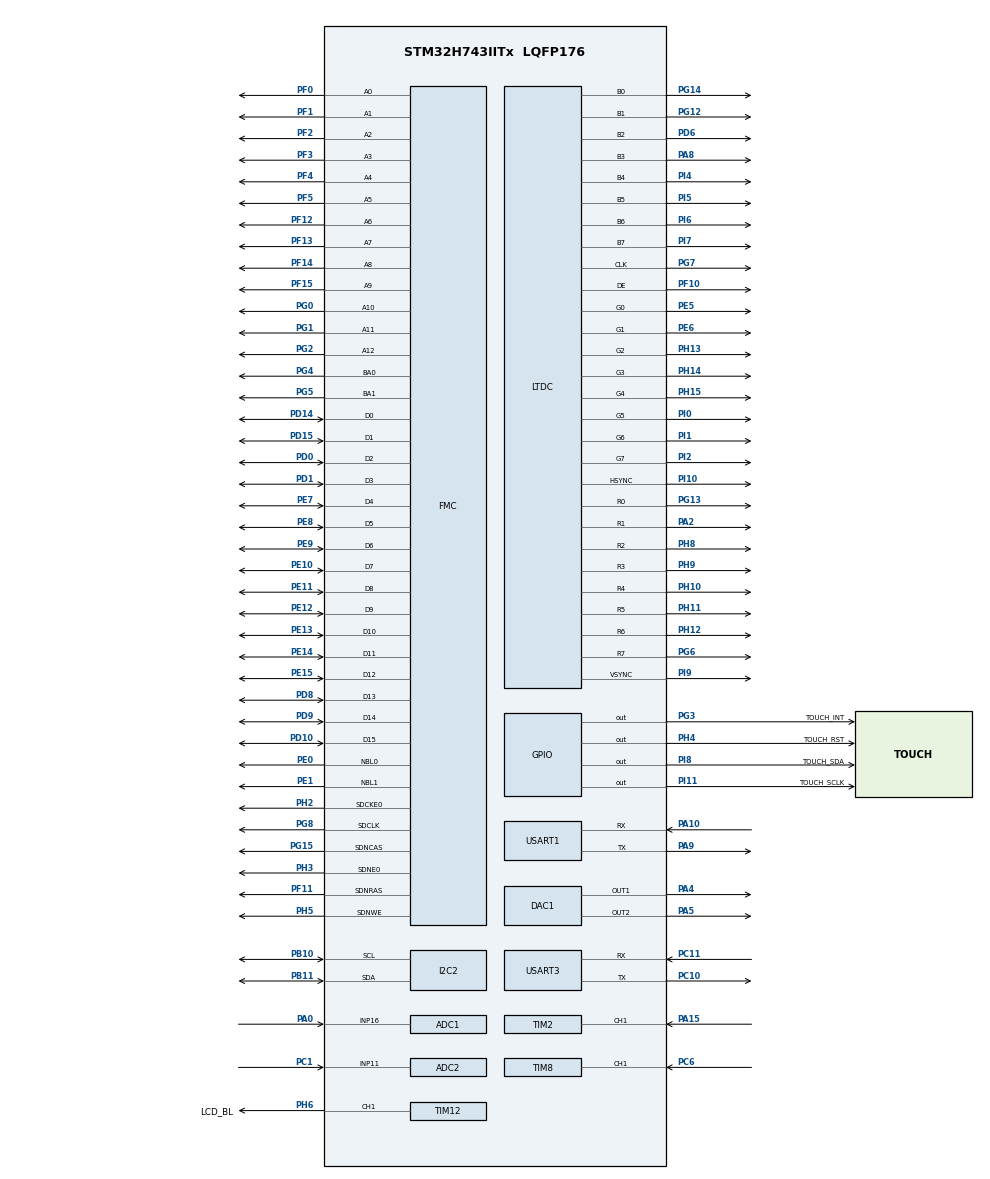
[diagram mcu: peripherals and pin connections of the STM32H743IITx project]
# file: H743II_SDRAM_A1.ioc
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ADC1.Channel-0\#ChannelRegularConversion=ADC_CHANNEL_16
ADC1.ConversionDataManagement=ADC_CONVERSIONDATA_DMA_CIRCULAR
ADC1.ExternalTrigConv=ADC_EXTERNALTRIG_T2_TRGO
ADC1.NbrOfConversionFlag=1
ADC1.OffsetNumber-0\#ChannelRegularConversion=ADC_OFFSET_NONE
ADC1.OffsetSignedSaturation-0\#ChannelRegularConversion=DISABLE
ADC1.Overrun=ADC_OVR_DATA_OVERWRITTEN
ADC1.Rank-0\#ChannelRegularConversion=1
ADC1.Resolution=ADC_RESOLUTION_8B
ADC1.SamplingTime-0\#ChannelRegularConversion=ADC_SAMPLETIME_1CYCLE_5
ADC1.master=1
ADC2.Channel-0\#ChannelRegularConversion=ADC_CHANNEL_11
ADC2.ConversionDataManagement=ADC_CONVERSIONDATA_DMA_CIRCULAR
ADC2.ExternalTrigConv=ADC_EXTERNALTRIG_T8_TRGO
ADC2.NbrOfConversionFlag=1
ADC2.OffsetNumber-0\#ChannelRegularConversion=ADC_OFFSET_NONE
ADC2.OffsetSignedSaturation-0\#ChannelRegularConversion=DISABLE
ADC2.Overrun=ADC_OVR_DATA_OVERWRITTEN
ADC2.Rank-0\#ChannelRegularConversion=1
ADC2.Resolution=ADC_RESOLUTION_8B
ADC2.SamplingTime-0\#ChannelRegularConversion=ADC_SAMPLETIME_1CYCLE_5
CORTEX_M7.AccessPermission-Cortex_Memory_Protection_Unit_Region0_Settings=MPU_REGION_FULL_ACCESS
CORTEX_M7.AccessPermission-Cortex_Memory_Protection_Unit_Region1_Settings=MPU_REGION_FULL_ACCESS
CORTEX_M7.AccessPermission-Cortex_Memory_Protection_Unit_Region2_Settings=MPU_REGION_FULL_ACCESS
CORTEX_M7.BaseAddress-Cortex_Memory_Protection_Unit_Region0_Settings=0x24000000
CORTEX_M7.BaseAddress-Cortex_Memory_Protection_Unit_Region1_Settings=0x30000000
CORTEX_M7.BaseAddress-Cortex_Memory_Protection_Unit_Region2_Settings=0xC0000000
CORTEX_M7.CPU_DCache=Enabled
CORTEX_M7.CPU_ICache=Enabled
CORTEX_M7.DisableExec-Cortex_Memory_Protection_Unit_Region0_Settings=MPU_INSTRUCTION_ACCESS_DISABLE
CORTEX_M7.DisableExec-Cortex_Memory_Protection_Unit_Region1_Settings=MPU_INSTRUCTION_ACCESS_DISABLE
CORTEX_M7.Enable-Cortex_Memory_Protection_Unit_Region0_Settings=MPU_REGION_ENABLE
CORTEX_M7.Enable-Cortex_Memory_Protection_Unit_Region1_Settings=MPU_REGION_ENABLE
CORTEX_M7.Enable-Cortex_Memory_Protection_Unit_Region2_Settings=MPU_REGION_ENABLE
CORTEX_M7.IsBufferable-Cortex_Memory_Protection_Unit_Region0_Settings=MPU_ACCESS_BUFFERABLE
CORTEX_M7.IsCacheable-Cortex_Memory_Protection_Unit_Region0_Settings=MPU_ACCESS_CACHEABLE
CORTEX_M7.MPU_Control=MPU_PRIVILEGED_DEFAULT
CORTEX_M7.Size-Cortex_Memory_Protection_Unit_Region0_Settings=MPU_REGION_SIZE_64KB
CORTEX_M7.Size-Cortex_Memory_Protection_Unit_Region1_Settings=MPU_REGION_SIZE_16KB
CORTEX_M7.Size-Cortex_Memory_Protection_Unit_Region2_Settings=MPU_REGION_SIZE_32MB
CORTEX_M7.TypeExtField-Cortex_Memory_Protection_Unit_Region1_Settings=MPU_TEX_LEVEL1
DAC1.DAC_Channel-DAC_OUT1=DAC_CHANNEL_1
DAC1.DAC_Channel-DAC_OUT2=DAC_CHANNEL_2
DAC1.DAC_Trigger-DAC_OUT1=DAC_TRIGGER_T2_TRGO
DAC1.DAC_Trigger-DAC_OUT2=DAC_TRIGGER_T8_TRGO
DMA2D.ColorMode=DMA2D_OUTPUT_ARGB8888
Dma.ADC1.0.Direction=DMA_PERIPH_TO_MEMORY
Dma.ADC1.0.EventEnable=DISABLE
Dma.ADC1.0.FIFOMode=DMA_FIFOMODE_DISABLE
Dma.ADC1.0.Instance=DMA1_Stream0
Dma.ADC1.0.MemDataAlignment=DMA_MDATAALIGN_BYTE
Dma.ADC1.0.MemInc=DMA_MINC_ENABLE
Dma.ADC1.0.Mode=DMA_CIRCULAR
Dma.ADC1.0.PeriphDataAlignment=DMA_PDATAALIGN_BYTE
Dma.ADC1.0.PeriphInc=DMA_PINC_DISABLE
Dma.ADC1.0.Polarity=HAL_DMAMUX_REQ_GEN_RISING
Dma.ADC1.0.Priority=DMA_PRIORITY_LOW
Dma.ADC1.0.RequestNumber=1
Dma.ADC1.0.SignalID=NONE
Dma.ADC1.0.SyncEnable=DISABLE
Dma.ADC1.0.SyncPolarity=HAL_DMAMUX_SYNC_NO_EVENT
Dma.ADC1.0.SyncRequestNumber=1
Dma.ADC1.0.SyncSignalID=NONE
Dma.ADC2.1.Direction=DMA_PERIPH_TO_MEMORY
Dma.ADC2.1.EventEnable=DISABLE
Dma.ADC2.1.FIFOMode=DMA_FIFOMODE_DISABLE
Dma.ADC2.1.Instance=DMA1_Stream1
Dma.ADC2.1.MemDataAlignment=DMA_MDATAALIGN_BYTE
Dma.ADC2.1.MemInc=DMA_MINC_ENABLE
Dma.ADC2.1.Mode=DMA_CIRCULAR
Dma.ADC2.1.PeriphDataAlignment=DMA_PDATAALIGN_BYTE
Dma.ADC2.1.PeriphInc=DMA_PINC_DISABLE
Dma.ADC2.1.Polarity=HAL_DMAMUX_REQ_GEN_RISING
Dma.ADC2.1.Priority=DMA_PRIORITY_LOW
Dma.ADC2.1.RequestNumber=1
Dma.ADC2.1.SignalID=NONE
Dma.ADC2.1.SyncEnable=DISABLE
Dma.ADC2.1.SyncPolarity=HAL_DMAMUX_SYNC_NO_EVENT
Dma.ADC2.1.SyncRequestNumber=1
Dma.ADC2.1.SyncSignalID=NONE
Dma.DAC1_CH1.2.Direction=DMA_MEMORY_TO_PERIPH
Dma.DAC1_CH1.2.EventEnable=DISABLE
Dma.DAC1_CH1.2.FIFOMode=DMA_FIFOMODE_DISABLE
Dma.DAC1_CH1.2.Instance=DMA1_Stream2
Dma.DAC1_CH1.2.MemDataAlignment=DMA_MDATAALIGN_HALFWORD
Dma.DAC1_CH1.2.MemInc=DMA_MINC_ENABLE
Dma.DAC1_CH1.2.Mode=DMA_CIRCULAR
Dma.DAC1_CH1.2.PeriphDataAlignment=DMA_PDATAALIGN_HALFWORD
Dma.DAC1_CH1.2.PeriphInc=DMA_PINC_DISABLE
Dma.DAC1_CH1.2.Polarity=HAL_DMAMUX_REQ_GEN_RISING
Dma.DAC1_CH1.2.Priority=DMA_PRIORITY_LOW
Dma.DAC1_CH1.2.RequestNumber=1
Dma.DAC1_CH1.2.SignalID=NONE
Dma.DAC1_CH1.2.SyncEnable=DISABLE
Dma.DAC1_CH1.2.SyncPolarity=HAL_DMAMUX_SYNC_NO_EVENT
Dma.DAC1_CH1.2.SyncRequestNumber=1
Dma.DAC1_CH1.2.SyncSignalID=NONE
Dma.DAC1_CH2.3.Direction=DMA_MEMORY_TO_PERIPH
Dma.DAC1_CH2.3.EventEnable=DISABLE
Dma.DAC1_CH2.3.FIFOMode=DMA_FIFOMODE_DISABLE
Dma.DAC1_CH2.3.Instance=DMA1_Stream3
Dma.DAC1_CH2.3.MemDataAlignment=DMA_MDATAALIGN_HALFWORD
Dma.DAC1_CH2.3.MemInc=DMA_MINC_ENABLE
Dma.DAC1_CH2.3.Mode=DMA_CIRCULAR
Dma.DAC1_CH2.3.PeriphDataAlignment=DMA_PDATAALIGN_HALFWORD
Dma.DAC1_CH2.3.PeriphInc=DMA_PINC_DISABLE
Dma.DAC1_CH2.3.Polarity=HAL_DMAMUX_REQ_GEN_RISING
Dma.DAC1_CH2.3.Priority=DMA_PRIORITY_LOW
Dma.DAC1_CH2.3.RequestNumber=1
Dma.DAC1_CH2.3.SignalID=NONE
Dma.DAC1_CH2.3.SyncEnable=DISABLE
Dma.DAC1_CH2.3.SyncPolarity=HAL_DMAMUX_SYNC_NO_EVENT
Dma.DAC1_CH2.3.SyncRequestNumber=1
Dma.DAC1_CH2.3.SyncSignalID=NONE
Dma.Request0=ADC1
Dma.Request1=ADC2
Dma.Request2=DAC1_CH1
Dma.Request3=DAC1_CH2
FMC.CASLatency1=FMC_SDRAM_CAS_LATENCY_3
FMC.ColumnBitsNumber1=FMC_SDRAM_COLUMN_BITS_NUM_9
FMC.ExitSelfRefreshDelay1=9
FMC.LoadToActiveDelay1=2
FMC.RCDDelay1=3
FMC.RPDelay1=3
FMC.RPDelay2=3
FMC.ReadBurst1=FMC_SDRAM_RBURST_ENABLE
FMC.ReadBurst2=FMC_SDRAM_RBURST_ENABLE
FMC.ReadPipeDelay1=FMC_SDRAM_RPIPE_DELAY_1
FMC.ReadPipeDelay2=FMC_SDRAM_RPIPE_DELAY_1
FMC.RowCycleDelay1=8
FMC.RowCycleDelay2=8
FMC.SDClockPeriod1=FMC_SDRAM_CLOCK_PERIOD_2
FMC.SDClockPeriod2=FMC_SDRAM_CLOCK_PERIOD_2
FMC.SelfRefreshTime1=6
FMC.WriteRecoveryTime1=2
I2C2.Timing=0x307075B1
LTDC.ActiveW=800
LTDC.Alpha_L0=255
LTDC.BlendingFactor1_L0=LTDC_BLENDING_FACTOR1_PAxCA
LTDC.BlendingFactor2_L0=LTDC_BLENDING_FACTOR2_PAxCA
LTDC.FBStartAdress_L0=0xC0000000
LTDC.HBP=80
LTDC.HFP=200
LTDC.HSync=1
LTDC.ImageHeight_L0=480
LTDC.ImageWidth_L0=800
LTDC.Layers=0
LTDC.PixelFormat_L0=LTDC_PIXEL_FORMAT_ARGB8888
LTDC.VBP=40
LTDC.VFP=22
LTDC.VSync=1
LTDC.WindowX1_L0=800
LTDC.WindowY1_L0=480
Mcu.Family=STM32H7
Mcu.Name=STM32H743IITx
Mcu.Package=LQFP176
NVIC.DMA1_Stream0_IRQn=true\:0\:0\:false\:false\:true\:false\:true\:true
NVIC.DMA1_Stream1_IRQn=true\:0\:0\:false\:false\:true\:false\:true\:true
NVIC.DMA1_Stream2_IRQn=true\:0\:0\:false\:false\:true\:false\:true\:true
NVIC.DMA1_Stream3_IRQn=true\:0\:0\:false\:false\:true\:false\:true\:true
NVIC.PriorityGroup=NVIC_PRIORITYGROUP_4
PA0.Mode=IN16-Single-Ended
PA0.Signal=ADC1_INP16
PA10.Mode=Asynchronous
PA10.Signal=USART1_RX
PA13\ (JTMS/SWDIO).Mode=Serial_Wire
PA13\ (JTMS/SWDIO).Signal=DEBUG_JTMS-SWDIO
PA14\ (JTCK/SWCLK).Mode=Serial_Wire
PA14\ (JTCK/SWCLK).Signal=DEBUG_JTCK-SWCLK
PA15\ (JTDI).Signal=S_TIM2_CH1_ETR
PA2.GPIO_Speed=GPIO_SPEED_FREQ_HIGH
PA2.Mode=RGB888
PA2.Signal=LTDC_R1
PA4.Signal=COMP_DAC11_group
PA5.Signal=COMP_DAC12_group
PA8.GPIO_Speed=GPIO_SPEED_FREQ_HIGH
PA8.Mode=RGB888
PA8.Signal=LTDC_B3
PA9.Mode=Asynchronous
PA9.Signal=USART1_TX
PB10.Mode=I2C
PB10.Signal=I2C2_SCL
PB11.Mode=I2C
PB11.Signal=I2C2_SDA
PC1.Signal=ADCx_INP11
PC10.Mode=Asynchronous
PC10.Signal=USART3_TX
PC11.Mode=Asynchronous
PC11.Signal=USART3_RX
PC14-OSC32_IN\ (OSC32_IN).Mode=LSE-External-Oscillator
PC14-OSC32_IN\ (OSC32_IN).Signal=RCC_OSC32_IN
PC15-OSC32_OUT\ (OSC32_OUT).Mode=LSE-External-Oscillator
PC15-OSC32_OUT\ (OSC32_OUT).Signal=RCC_OSC32_OUT
PC6.Signal=S_TIM8_CH1
PD0.Signal=FMC_D2_DA2
PD1.Signal=FMC_D3_DA3
PD10.Signal=FMC_D15_DA15
PD14.Signal=FMC_D0_DA0
PD15.Signal=FMC_D1_DA1
PD6.GPIO_Speed=GPIO_SPEED_FREQ_HIGH
PD6.Mode=RGB888
PD6.Signal=LTDC_B2
PD8.Signal=FMC_D13_DA13
PD9.Signal=FMC_D14_DA14
PE0.Signal=FMC_NBL0
PE1.Signal=FMC_NBL1
PE10.Signal=FMC_D7_DA7
PE11.Signal=FMC_D8_DA8
PE12.Signal=FMC_D9_DA9
PE13.Signal=FMC_D10_DA10
PE14.Signal=FMC_D11_DA11
PE15.Signal=FMC_D12_DA12
PE5.GPIO_Speed=GPIO_SPEED_FREQ_HIGH
PE5.Mode=RGB888
PE5.Signal=LTDC_G0
PE6.GPIO_Speed=GPIO_SPEED_FREQ_HIGH
PE6.Mode=RGB888
PE6.Signal=LTDC_G1
PE7.Signal=FMC_D4_DA4
PE8.Signal=FMC_D5_DA5
PE9.Signal=FMC_D6_DA6
PF0.Signal=FMC_A0
PF1.Signal=FMC_A1
PF10.GPIO_Speed=GPIO_SPEED_FREQ_HIGH
PF10.Mode=RGB888
PF10.Signal=LTDC_DE
PF11.Signal=FMC_SDNRAS
PF12.Signal=FMC_A6
PF13.Signal=FMC_A7
PF14.Signal=FMC_A8
PF15.Signal=FMC_A9
PF2.Signal=FMC_A2
PF3.Signal=FMC_A3
PF4.Signal=FMC_A4
PF5.Signal=FMC_A5
PG0.Signal=FMC_A10
PG1.Signal=FMC_A11
PG12.GPIO_Speed=GPIO_SPEED_FREQ_HIGH
PG12.Mode=RGB888
PG12.Signal=LTDC_B1
PG13.GPIO_Speed=GPIO_SPEED_FREQ_HIGH
PG13.Mode=RGB888
PG13.Signal=LTDC_R0
PG14.GPIO_Speed=GPIO_SPEED_FREQ_HIGH
PG14.Mode=RGB888
PG14.Signal=LTDC_B0
PG15.Signal=FMC_SDNCAS
PG2.Signal=FMC_A12
PG3.GPIO_Label=TOUCH_INT
PG3.GPIO_ModeDefaultOutputPP=GPIO_MODE_OUTPUT_PP
PG3.GPIO_PuPd=GPIO_NOPULL
PG3.GPIO_Speed=GPIO_SPEED_FREQ_LOW
PG3.PinState=GPIO_PIN_RESET
PG3.Signal=GPIO_Output
PG4.Signal=FMC_A14_BA0
PG5.Signal=FMC_A15_BA1
PG6.GPIO_Speed=GPIO_SPEED_FREQ_HIGH
PG6.Mode=RGB888
PG6.Signal=LTDC_R7
PG7.GPIO_Speed=GPIO_SPEED_FREQ_HIGH
PG7.Mode=RGB888
PG7.Signal=LTDC_CLK
PG8.Signal=FMC_SDCLK
PH0-OSC_IN\ (PH0).Mode=HSE-External-Oscillator
PH0-OSC_IN\ (PH0).Signal=RCC_OSC_IN
PH1-OSC_OUT\ (PH1).Mode=HSE-External-Oscillator
PH1-OSC_OUT\ (PH1).Signal=RCC_OSC_OUT
PH10.GPIO_Speed=GPIO_SPEED_FREQ_HIGH
PH10.Mode=RGB888
PH10.Signal=LTDC_R4
PH11.GPIO_Speed=GPIO_SPEED_FREQ_HIGH
PH11.Mode=RGB888
PH11.Signal=LTDC_R5
PH12.GPIO_Speed=GPIO_SPEED_FREQ_HIGH
PH12.Mode=RGB888
PH12.Signal=LTDC_R6
PH13.GPIO_Speed=GPIO_SPEED_FREQ_HIGH
PH13.Mode=RGB888
PH13.Signal=LTDC_G2
PH14.GPIO_Speed=GPIO_SPEED_FREQ_HIGH
PH14.Mode=RGB888
PH14.Signal=LTDC_G3
PH15.GPIO_Speed=GPIO_SPEED_FREQ_HIGH
PH15.Mode=RGB888
PH15.Signal=LTDC_G4
PH2.Mode=SdramChipSelect1_1
PH2.Signal=FMC_SDCKE0
PH3.Mode=SdramChipSelect1_1
PH3.Signal=FMC_SDNE0
PH4.GPIO_Label=TOUCH_RST
PH4.GPIO_Speed=GPIO_SPEED_FREQ_LOW
PH4.PinState=GPIO_PIN_SET
PH4.Signal=GPIO_Output
PH5.Signal=FMC_SDNWE
PH6.GPIO_Label=LCD_BL
PH6.Signal=S_TIM12_CH1
PH8.GPIO_Speed=GPIO_SPEED_FREQ_HIGH
PH8.Mode=RGB888
PH8.Signal=LTDC_R2
PH9.GPIO_Speed=GPIO_SPEED_FREQ_HIGH
PH9.Mode=RGB888
PH9.Signal=LTDC_R3
PI0.GPIO_Speed=GPIO_SPEED_FREQ_HIGH
PI0.Mode=RGB888
PI0.Signal=LTDC_G5
PI1.GPIO_Speed=GPIO_SPEED_FREQ_HIGH
PI1.Mode=RGB888
PI1.Signal=LTDC_G6
PI10.GPIO_Speed=GPIO_SPEED_FREQ_HIGH
PI10.Mode=RGB888
PI10.Signal=LTDC_HSYNC
PI11.GPIO_Label=TOUCH_SCLK
PI11.GPIO_ModeDefaultOutputPP=GPIO_MODE_OUTPUT_OD
PI11.GPIO_PuPd=GPIO_NOPULL
PI11.GPIO_Speed=GPIO_SPEED_FREQ_LOW
PI11.PinState=GPIO_PIN_SET
PI11.Signal=GPIO_Output
PI2.GPIO_Speed=GPIO_SPEED_FREQ_HIGH
PI2.Mode=RGB888
PI2.Signal=LTDC_G7
PI4.GPIO_Speed=GPIO_SPEED_FREQ_HIGH
PI4.Mode=RGB888
PI4.Signal=LTDC_B4
PI5.GPIO_Speed=GPIO_SPEED_FREQ_HIGH
PI5.Mode=RGB888
PI5.Signal=LTDC_B5
PI6.GPIO_Speed=GPIO_SPEED_FREQ_HIGH
PI6.Mode=RGB888
PI6.Signal=LTDC_B6
PI7.GPIO_Speed=GPIO_SPEED_FREQ_HIGH
PI7.Mode=RGB888
PI7.Signal=LTDC_B7
PI8.GPIO_Label=TOUCH_SDA
PI8.Signal=GPIO_Output
PI9.GPIO_Speed=GPIO_SPEED_FREQ_HIGH
PI9.Mode=RGB888
PI9.Signal=LTDC_VSYNC
ProjectManager.HeapSize=0x1600
ProjectManager.StackSize=0x2000
ProjectManager.TargetToolchain=MDK-ARM V5.32
RCC.ADCFreq_Value=75000000
RCC.APB1Freq_Value=120000000
RCC.APB2Freq_Value=120000000
RCC.APB3Freq_Value=120000000
RCC.APB4Freq_Value=120000000
RCC.CortexFreq_Value=480000000
RCC.D1PPRE=RCC_APB3_DIV2
RCC.D2PPRE1=RCC_APB1_DIV2
RCC.D2PPRE2=RCC_APB2_DIV2
RCC.D3PPRE=RCC_APB4_DIV2
RCC.DIVM1=5
RCC.DIVM2=2
RCC.DIVM3=25
RCC.DIVN1=192
RCC.DIVN2=12
RCC.DIVN3=264
RCC.DIVQ3=8
RCC.DIVR3=8
RCC.HCLKFreq_Value=240000000
RCC.HPRE=RCC_HCLK_DIV2
RCC.PLL2FRACN=0
RCC.PLL3FRACN=0
RCC.PLLFRACN=0
RCC.PLLSourceVirtual=RCC_PLLSOURCE_HSE
RCC.SYSCLKFreq_VALUE=480000000
RCC.SYSCLKSource=RCC_SYSCLKSOURCE_PLLCLK
RCC.USBFreq_Value=480000000
SH.ADCx_INP11.0=ADC2_INP11,IN11-Single-Ended
SH.COMP_DAC11_group.0=DAC1_OUT1,DAC_OUT1
SH.COMP_DAC12_group.0=DAC1_OUT2,DAC_OUT2
SH.FMC_A0.0=FMC_A0,13b-sda1
SH.FMC_A1.0=FMC_A1,13b-sda1
SH.FMC_A10.0=FMC_A10,13b-sda1
SH.FMC_A11.0=FMC_A11,13b-sda1
SH.FMC_A12.0=FMC_A12,13b-sda1
SH.FMC_A14_BA0.0=FMC_BA0,FourSdramBanks1
SH.FMC_A15_BA1.0=FMC_BA1,FourSdramBanks1
SH.FMC_A2.0=FMC_A2,13b-sda1
SH.FMC_A3.0=FMC_A3,13b-sda1
SH.FMC_A4.0=FMC_A4,13b-sda1
SH.FMC_A5.0=FMC_A5,13b-sda1
SH.FMC_A6.0=FMC_A6,13b-sda1
SH.FMC_A7.0=FMC_A7,13b-sda1
SH.FMC_A8.0=FMC_A8,13b-sda1
SH.FMC_A9.0=FMC_A9,13b-sda1
SH.FMC_D0_DA0.0=FMC_D0,sd-16b-d1
SH.FMC_D10_DA10.0=FMC_D10,sd-16b-d1
SH.FMC_D11_DA11.0=FMC_D11,sd-16b-d1
SH.FMC_D12_DA12.0=FMC_D12,sd-16b-d1
SH.FMC_D13_DA13.0=FMC_D13,sd-16b-d1
SH.FMC_D14_DA14.0=FMC_D14,sd-16b-d1
SH.FMC_D15_DA15.0=FMC_D15,sd-16b-d1
SH.FMC_D1_DA1.0=FMC_D1,sd-16b-d1
SH.FMC_D2_DA2.0=FMC_D2,sd-16b-d1
SH.FMC_D3_DA3.0=FMC_D3,sd-16b-d1
SH.FMC_D4_DA4.0=FMC_D4,sd-16b-d1
SH.FMC_D5_DA5.0=FMC_D5,sd-16b-d1
SH.FMC_D6_DA6.0=FMC_D6,sd-16b-d1
SH.FMC_D7_DA7.0=FMC_D7,sd-16b-d1
SH.FMC_D8_DA8.0=FMC_D8,sd-16b-d1
SH.FMC_D9_DA9.0=FMC_D9,sd-16b-d1
SH.FMC_NBL0.0=FMC_NBL0,Sd2ByteEnable1
SH.FMC_NBL1.0=FMC_NBL1,Sd2ByteEnable1
SH.FMC_SDCLK.0=FMC_SDCLK,13b-sda1
SH.FMC_SDNCAS.0=FMC_SDNCAS,13b-sda1
SH.FMC_SDNRAS.0=FMC_SDNRAS,13b-sda1
SH.FMC_SDNWE.0=FMC_SDNWE,13b-sda1
SH.S_TIM12_CH1.0=TIM12_CH1,PWM Generation1 CH1
SH.S_TIM2_CH1_ETR.0=TIM2_CH1,TriggerSource_TI1FP1
SH.S_TIM8_CH1.0=TIM8_CH1,TriggerSource_TI1FP1
TIM12.AutoReloadPreload=TIM_AUTORELOAD_PRELOAD_ENABLE
TIM12.Channel-PWM\ Generation1\ CH1=TIM_CHANNEL_1
TIM12.Period=1000-1
TIM12.Prescaler=120-1
TIM12.Pulse-PWM\ Generation1\ CH1=500
TIM2.Period=2-1
TIM2.TIM_MasterOutputTrigger=TIM_TRGO_UPDATE
TIM8.Period=2-1
TIM8.TIM_MasterOutputTrigger=TIM_TRGO_UPDATE
USART1.VirtualMode-Asynchronous=VM_ASYNC
USART3.VirtualMode-Asynchronous=VM_ASYNC
VP_DMA2D_VS_DMA2D.Mode=DMA2D_Activate
VP_MEMORYMAP_VS_MEMORYMAP.Mode=CurAppReg
VP_TIM12_VS_ClockSourceINT.Mode=Internal
VP_TIM2_VS_ControllerModeClock.Mode=Clock Mode
VP_TIM8_VS_ControllerModeClock.Mode=Clock Mode
board=custom

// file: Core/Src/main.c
/* USER CODE BEGIN Header */
/**
  ******************************************************************************
  * @file           : main.c
  * @brief          : Main program body
  ******************************************************************************
  * @attention
  *
  * Copyright (c) 2026 STMicroelectronics.
  * All rights reserved.
  *
  * This software is licensed under terms that can be found in the LICENSE file
  * in the root directory of this software component.
  * If no LICENSE file comes with this software, it is provided AS-IS.
  *
  ******************************************************************************
  */
/* USER CODE END Header */
#include "main.h"
#include "adc.h"
#include "dac.h"
#include "dma.h"
#include "dma2d.h"
#include "i2c.h"
#include "ltdc.h"
#include "tim.h"
#include "usart.h"
#include "gpio.h"
#include "fmc.h"

/* USER CODE BEGIN Includes */
#include "new_test1.h"
/* USER CODE END Includes */

void SystemClock_Config(void);
void PeriphCommonClock_Config(void);
static void MPU_Config(void);

int main(void)
{

  /* MPU Configuration--------------------------------------------------------*/
  MPU_Config();

  /* Enable the CPU Cache */

  /* Enable I-Cache---------------------------------------------------------*/
  SCB_EnableICache();

  /* Enable D-Cache---------------------------------------------------------*/
  SCB_EnableDCache();

  /* MCU Configuration--------------------------------------------------------*/

  /* Reset of all peripherals, Initializes the Flash interface and the Systick. */
  HAL_Init();

  /* Configure the system clock */
  SystemClock_Config();

  /* Configure the peripherals common clocks */
  PeriphCommonClock_Config();

  /* Initialize all configured peripherals */
  MX_GPIO_Init();
  MX_DMA_Init();
  MX_FMC_Init();
  MX_USART1_UART_Init();
  MX_TIM12_Init();
  MX_LTDC_Init();
  MX_DMA2D_Init();
  MX_TIM2_Init();
  MX_TIM8_Init();
  MX_ADC1_Init();
  MX_ADC2_Init();
  MX_DAC1_Init();
  MX_I2C2_Init();
  MX_USART3_UART_Init();
  /* USER CODE BEGIN 2 */
	Test_Init();
	Test_Loop();
  /* USER CODE END 2 */

  /* Infinite loop */
  while (1)
  {

  }
}

void SystemClock_Config(void)
{
  RCC_OscInitTypeDef RCC_OscInitStruct = {0};
  RCC_ClkInitTypeDef RCC_ClkInitStruct = {0};

  /** Supply configuration update enable
  */
  HAL_PWREx_ConfigSupply(PWR_LDO_SUPPLY);

  /** Configure the main internal regulator output voltage
  */
  __HAL_PWR_VOLTAGESCALING_CONFIG(PWR_REGULATOR_VOLTAGE_SCALE0);

  while(!__HAL_PWR_GET_FLAG(PWR_FLAG_VOSRDY)) {}

  /** Initializes the RCC Oscillators according to the specified parameters
  * in the RCC_OscInitTypeDef structure.
  */
  RCC_OscInitStruct.OscillatorType = RCC_OSCILLATORTYPE_HSE;
  RCC_OscInitStruct.HSEState = RCC_HSE_ON;
  RCC_OscInitStruct.PLL.PLLState = RCC_PLL_ON;
  RCC_OscInitStruct.PLL.PLLSource = RCC_PLLSOURCE_HSE;
  RCC_OscInitStruct.PLL.PLLM = 5;
  RCC_OscInitStruct.PLL.PLLN = 192;
  RCC_OscInitStruct.PLL.PLLP = 2;
  RCC_OscInitStruct.PLL.PLLQ = 2;
  RCC_OscInitStruct.PLL.PLLR = 2;
  RCC_OscInitStruct.PLL.PLLRGE = RCC_PLL1VCIRANGE_2;
  RCC_OscInitStruct.PLL.PLLVCOSEL = RCC_PLL1VCOWIDE;
  RCC_OscInitStruct.PLL.PLLFRACN = 0;
  if (HAL_RCC_OscConfig(&RCC_OscInitStruct) != HAL_OK)
  {
    Error_Handler();
  }

  /** Initializes the CPU, AHB and APB buses clocks
  */
  RCC_ClkInitStruct.ClockType = RCC_CLOCKTYPE_HCLK|RCC_CLOCKTYPE_SYSCLK
                              |RCC_CLOCKTYPE_PCLK1|RCC_CLOCKTYPE_PCLK2
                              |RCC_CLOCKTYPE_D3PCLK1|RCC_CLOCKTYPE_D1PCLK1;
  RCC_ClkInitStruct.SYSCLKSource = RCC_SYSCLKSOURCE_PLLCLK;
  RCC_ClkInitStruct.SYSCLKDivider = RCC_SYSCLK_DIV1;
  RCC_ClkInitStruct.AHBCLKDivider = RCC_HCLK_DIV2;
  RCC_ClkInitStruct.APB3CLKDivider = RCC_APB3_DIV2;
  RCC_ClkInitStruct.APB1CLKDivider = RCC_APB1_DIV2;
  RCC_ClkInitStruct.APB2CLKDivider = RCC_APB2_DIV2;
  RCC_ClkInitStruct.APB4CLKDivider = RCC_APB4_DIV2;

  if (HAL_RCC_ClockConfig(&RCC_ClkInitStruct, FLASH_LATENCY_4) != HAL_OK)
  {
    Error_Handler();
  }
}

void PeriphCommonClock_Config(void)
{
  RCC_PeriphCLKInitTypeDef PeriphClkInitStruct = {0};

  /** Initializes the peripherals clock
  */
  PeriphClkInitStruct.PeriphClockSelection = RCC_PERIPHCLK_ADC;
  PeriphClkInitStruct.PLL2.PLL2M = 2;
  PeriphClkInitStruct.PLL2.PLL2N = 12;
  PeriphClkInitStruct.PLL2.PLL2P = 2;
  PeriphClkInitStruct.PLL2.PLL2Q = 2;
  PeriphClkInitStruct.PLL2.PLL2R = 2;
  PeriphClkInitStruct.PLL2.PLL2RGE = RCC_PLL2VCIRANGE_3;
  PeriphClkInitStruct.PLL2.PLL2VCOSEL = RCC_PLL2VCOMEDIUM;
  PeriphClkInitStruct.PLL2.PLL2FRACN = 0;
  PeriphClkInitStruct.AdcClockSelection = RCC_ADCCLKSOURCE_PLL2;
  if (HAL_RCCEx_PeriphCLKConfig(&PeriphClkInitStruct) != HAL_OK)
  {
    Error_Handler();
  }
}

 /* MPU Configuration */

void MPU_Config(void)
{
  MPU_Region_InitTypeDef MPU_InitStruct = {0};

  /* Disables the MPU */
  HAL_MPU_Disable();

  /** Initializes and configures the Region and the memory to be protected
  */
  MPU_InitStruct.Enable = MPU_REGION_ENABLE;
  MPU_InitStruct.Number = MPU_REGION_NUMBER0;
  MPU_InitStruct.BaseAddress = 0x24000000;
  MPU_InitStruct.Size = MPU_REGION_SIZE_64KB;
  MPU_InitStruct.SubRegionDisable = 0x0;
  MPU_InitStruct.TypeExtField = MPU_TEX_LEVEL0;
  MPU_InitStruct.AccessPermission = MPU_REGION_FULL_ACCESS;
  MPU_InitStruct.DisableExec = MPU_INSTRUCTION_ACCESS_DISABLE;
  MPU_InitStruct.IsShareable = MPU_ACCESS_NOT_SHAREABLE;
  MPU_InitStruct.IsCacheable = MPU_ACCESS_CACHEABLE;
  MPU_InitStruct.IsBufferable = MPU_ACCESS_BUFFERABLE;

  HAL_MPU_ConfigRegion(&MPU_InitStruct);

  /** Initializes and configures the Region and the memory to be protected
  */
  MPU_InitStruct.Number = MPU_REGION_NUMBER1;
  MPU_InitStruct.BaseAddress = 0x30000000;
  MPU_InitStruct.Size = MPU_REGION_SIZE_16KB;
  MPU_InitStruct.TypeExtField = MPU_TEX_LEVEL1;
  MPU_InitStruct.IsCacheable = MPU_ACCESS_NOT_CACHEABLE;
  MPU_InitStruct.IsBufferable = MPU_ACCESS_NOT_BUFFERABLE;

  HAL_MPU_ConfigRegion(&MPU_InitStruct);

  /** Initializes and configures the Region and the memory to be protected
  */
  MPU_InitStruct.Number = MPU_REGION_NUMBER2;
  MPU_InitStruct.BaseAddress = 0xC0000000;
  MPU_InitStruct.Size = MPU_REGION_SIZE_32MB;
  MPU_InitStruct.TypeExtField = MPU_TEX_LEVEL0;
  MPU_InitStruct.DisableExec = MPU_INSTRUCTION_ACCESS_ENABLE;

  HAL_MPU_ConfigRegion(&MPU_InitStruct);
  /* Enables the MPU */
  HAL_MPU_Enable(MPU_PRIVILEGED_DEFAULT);

}

void Error_Handler(void)
{
  __disable_irq();
  while (1)
  {
  }
}
